AUTOSAR XML (schema 314)
package /ComponentType
  internal behavior Sa_TmprlMon_InternalBehavior: component=Sa_TmprlMon
    timing event TMT_TmprlMon_Per1: start-on-event=TmprlMon_Per1, period=0.002
    timing event TMT_TmprlMon_Per2: mode-dependency=dependent-on-mode=[SystemState.Mode.DISABLE, SystemState.Mode.OFF, SystemState.Mode.OPERATE], start-on-event=TmprlMon_Per2, period=0.002
    timing event TMT_TmprlMon_Per3: mode-dependency=dependent-on-mode=[SystemState.Mode.OFF, SystemState.Mode.WARMINIT], start-on-event=TmprlMon_Per3, period=0.01
    mode switch event MST_TmprlMon_Trns1_0: start-on-event=TmprlMon_Trns1, activation=ENTRY, mode=SystemState.Mode.WARMINIT
    mode switch event MST_TmprlMon_Trns2_0: start-on-event=TmprlMon_Trns2, activation=ENTRY, mode=SystemState.Mode.DISABLE
    port-api-options:
      enable-take-address=false, indirect-api=false, port=FetDrvCntl
      enable-take-address=false, indirect-api=false, port=NxtrDiagMgr
      enable-take-address=false, indirect-api=false, port=PwrSwitchEn
      enable-take-address=false, indirect-api=false, port=SysFault2
      enable-take-address=false, indirect-api=false, port=SysFault3
      enable-take-address=false, indirect-api=false, port=SystemState
      enable-take-address=false, indirect-api=false, port=SystemTime
      enable-take-address=false, indirect-api=false, port=TMFTestComplete
      enable-take-address=false, indirect-api=false, port=TMFTestStart
      enable-take-address=false, indirect-api=false, port=TmprlMon_Per1_CP0
      enable-take-address=false, indirect-api=false, port=WdMonitor
      enable-take-address=false, indirect-api=false, port=WdReset
    5 x runnable:
      TmprlMon_Per1
        sync call SC_TmprlMon_Per1_CP0_CheckpointReached: operation=TmprlMon_Per1_CP0.CheckpointReached, timeout=0
        sync call SC_WdMonitor_OP_SET: operation=WdMonitor.OP_SET, timeout=0
      TmprlMon_Per2
        data read access READ_TMFTestStart_Cnt_lgc: data-element=TMFTestStart.Cnt_lgc
        data write access WRITE_TMFTestComplete_Cnt_lgc: data-element=TMFTestComplete.Cnt_lgc
        8 x sync call, all with timeout=0:
          SC_FetDrvCntl_OP_GET: operation=FetDrvCntl.OP_GET
          SC_NxtrDiagMgr_SetNTCStatus: operation=NxtrDiagMgr.SetNTCStatus
          SC_PwrSwitchEn_OP_GET: operation=PwrSwitchEn.OP_GET
          SC_SysFault2_OP_SET: operation=SysFault2.OP_SET
          SC_SysFault3_OP_SET: operation=SysFault3.OP_SET
          SC_SystemTime_DtrmnElapsedTime_mS_u16: operation=SystemTime.DtrmnElapsedTime_mS_u16
          SC_SystemTime_GetSystemTime_mS_u32: operation=SystemTime.GetSystemTime_mS_u32
          SC_WdReset_OP_SET: operation=WdReset.OP_SET
      TmprlMon_Per3
        5 x sync call, all with timeout=0:
          SC_FetDrvCntl_OP_GET: operation=FetDrvCntl.OP_GET
          SC_NxtrDiagMgr_SetNTCStatus: operation=NxtrDiagMgr.SetNTCStatus
          SC_PwrSwitchEn_OP_GET: operation=PwrSwitchEn.OP_GET
          SC_SysFault2_OP_GET: operation=SysFault2.OP_GET
          SC_SysFault3_OP_GET: operation=SysFault3.OP_GET
      TmprlMon_Trns1
        data write access WRITE_TMFTestComplete_Cnt_lgc: data-element=TMFTestComplete.Cnt_lgc
        sync call SC_SystemTime_GetSystemTime_mS_u32: operation=SystemTime.GetSystemTime_mS_u32, timeout=0
      TmprlMon_Trns2
        sync call SC_SysFault2_OP_SET: operation=SysFault2.OP_SET, timeout=0
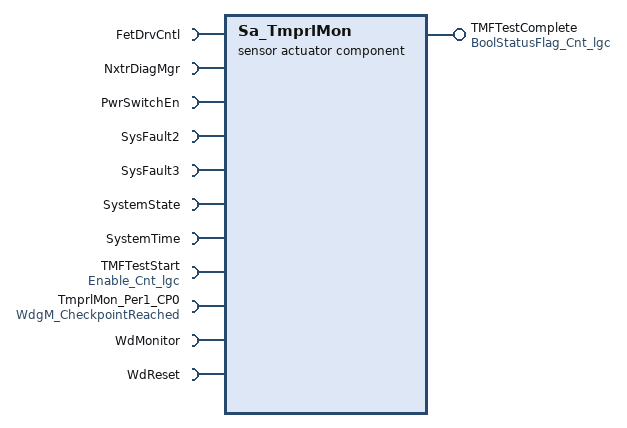
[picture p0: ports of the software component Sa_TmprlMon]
  sensor actuator software component type Sa_TmprlMon
    provide port TMFTestComplete: unqueued-sender-com-spec{data-element=Cnt_lgc, can-invalidate=false, init-value=D_FALSE_CNT_LGC}, provided-interface=BoolStatusFlag_Cnt_lgc
    11 x require port:
      FetDrvCntl: client-com-spec=OP_GET, required-interface=FetDrvCntl
      NxtrDiagMgr: required-com-specs=[GetNTCActive, GetNTCFailed, GetNTCStatus, SetNTCStatus], required-interface=NxtrDiagMgr
      PwrSwitchEn: client-com-spec=OP_GET, required-interface=PwrSwitchEn
      SysFault2: required-com-specs=[OP_GET, OP_SET], required-interface=SysFault2
      SysFault3: required-com-specs=[OP_GET, OP_SET], required-interface=SysFault3
      SystemState: required-interface=SystemState
      SystemTime: required-interface=SystemTime
        required-com-specs:
          DtrmnElapsedTime_mS_u16
          DtrmnElapsedTime_mS_u32
          DtrmnElapsedTime_uS_u16
          DtrmnElapsedTime_uS_u32
          GetSystemTime_mS_u32
          GetSystemTime_uS_u32
      TMFTestStart: unqueued-receiver-com-spec{data-element=Cnt_lgc, init-value=D_FALSE_CNT_LGC}, required-interface=Enable_Cnt_lgc
      TmprlMon_Per1_CP0: client-com-spec=CheckpointReached, required-interface=WdgM_CheckpointReached
      WdMonitor: client-com-spec=OP_SET, required-interface=WdMonitor
      WdReset: client-com-spec=OP_SET, required-interface=WdReset
  swc implementation Sa_TmprlMon_Implementation: behavior=Sa_TmprlMon_InternalBehavior
    code-descriptors:
      code Code: type=SRC
